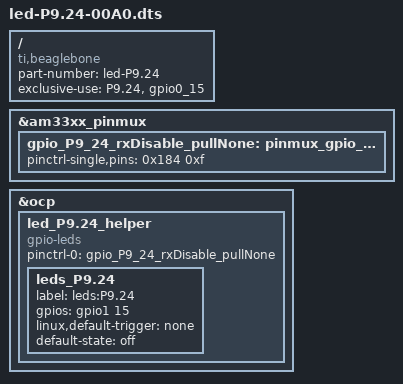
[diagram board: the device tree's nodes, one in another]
/*
* Easy gpio mux control of "P9.24" ("gpio0_15")
*/
/dts-v1/;
/plugin/;

/ {
	compatible = "ti,beaglebone", "ti,beaglebone-black";

	/* identification */
	part-number = "led-P9.24";
	/* version = "00A0"; */

	/* state the resources this cape uses */
	exclusive-use =
		/* the pin header uses */
		"P9.24",

		/* the hardware IP uses */
		"gpio0_15";
	
	
	/* rxDisable_pullNone state */
	fragment@0 {
		target = <&am33xx_pinmux>;
		__overlay__ {
			gpio_P9_24_rxDisable_pullNone: pinmux_gpio_P9.24_rxDisable_pullNone {
				pinctrl-single,pins = <
					0x184 0xf
				>;
			};
		};
	};

	fragment@1 {
		target = <&ocp>;
		__overlay__ {
			led_P9.24_helper {
				compatible = "gpio-leds";
				pinctrl-names = "default";
				pinctrl-0 = <&gpio_P9_24_rxDisable_pullNone>;
				
				leds_P9.24 {
					label = "leds:P9.24";
					gpios = <&gpio1 15 0>;
					linux,default-trigger = "none";
					default-state = "off";
				};
			};
			
		};
	};

};
